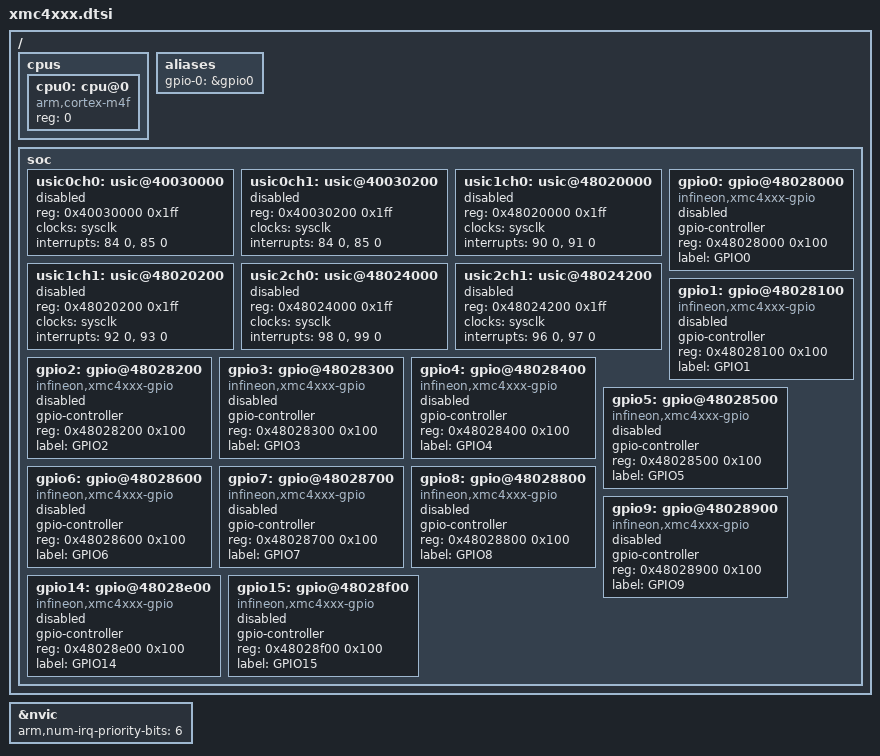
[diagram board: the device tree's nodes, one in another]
/*
 * Copyright (c) 2020 Linumiz
 * Author: Parthiban Nallathambi <parthiban@linumiz.com>
 *
 * SPDX-License-Identifier: Apache-2.0
 */

#include <arm/armv7-m.dtsi>
#include <dt-bindings/gpio/gpio.h>

/ {
	cpus {
		#address-cells = <1>;
		#size-cells = <0>;

		cpu0: cpu@0 {
			compatible = "arm,cortex-m4f";
			reg = <0>;
		};
	};

	aliases {
		gpio-0 = &gpio0; 	
	};

	soc {
		usic0ch0: usic@40030000 {
			#address-cells = <1>;
			#size-cells = <0>;
			reg = <0x40030000 0x1ff>;
			clocks = <&sysclk>;
			status = "disabled";
			interrupts = <84 0>, <85 0>;
			interrupt-names = "SR0", "SR1";
		};

		usic0ch1: usic@40030200 {
			#address-cells = <1>;
			#size-cells = <0>;
			reg = <0x40030200 0x1ff>;
			clocks = <&sysclk>;
			status = "disabled";
			interrupts = <84 0>, <85 0>;
			interrupt-names = "SR0", "SR1";
		};

		usic1ch0: usic@48020000 {
			#address-cells = <1>;
			#size-cells = <0>;
			reg = <0x48020000 0x1ff>;
			clocks = <&sysclk>;
			status = "disabled";
			interrupts = <90 0>, <91 0>;
			interrupt-names = "SR0", "SR1";
		};

		usic1ch1: usic@48020200 {
			#address-cells = <1>;
			#size-cells = <0>;
			reg = <0x48020200 0x1ff>;
			clocks = <&sysclk>;
			status = "disabled";
			interrupts = <92 0>, <93 0>;
			interrupt-names = "SR0", "SR1";
		};

		usic2ch0: usic@48024000 {
			#address-cells = <1>;
			#size-cells = <0>;
			reg = <0x48024000 0x1ff>;
			clocks = <&sysclk>;
			status = "disabled";
			interrupts = <98 0>, <99 0>;
			interrupt-names = "SR0", "SR1";
		};

		usic2ch1: usic@48024200 {
			#address-cells = <1>;
			#size-cells = <0>;
			reg = <0x48024200 0x1ff>;
			clocks = <&sysclk>;
			status = "disabled";
			interrupts = <96 0>, <97 0>;
			interrupt-names = "SR0", "SR1";
		};

		/* GPIO Interface */
		gpio0: gpio@48028000 {
			compatible = "infineon,xmc4xxx-gpio";
			gpio-controller;
			#gpio-cells = <2>;
			reg = <0x48028000 0x100>;
			label = "GPIO0";
			status = "disabled";
		};

		gpio1: gpio@48028100 {
			compatible = "infineon,xmc4xxx-gpio";
			gpio-controller;
			#gpio-cells = <2>;
			reg = <0x48028100 0x100>;
			label = "GPIO1";
			status = "disabled";
		};

		gpio2: gpio@48028200 {
			compatible = "infineon,xmc4xxx-gpio";
			gpio-controller;
			#gpio-cells = <2>;
			reg = <0x48028200 0x100>;
			label = "GPIO2";
			status = "disabled";
		};

		gpio3: gpio@48028300 {
			compatible = "infineon,xmc4xxx-gpio";
			gpio-controller;
			#gpio-cells = <2>;
			reg = <0x48028300 0x100>;
			label = "GPIO3";
			status = "disabled";
		};

		gpio4: gpio@48028400 {
			compatible = "infineon,xmc4xxx-gpio";
			gpio-controller;
			#gpio-cells = <2>;
			reg = <0x48028400 0x100>;
			label = "GPIO4";
			status = "disabled";
		};

		gpio5: gpio@48028500 {
			compatible = "infineon,xmc4xxx-gpio";
			gpio-controller;
			#gpio-cells = <2>;
			reg = <0x48028500 0x100>;
			label = "GPIO5";
			status = "disabled";
		};

		gpio6: gpio@48028600 {
			compatible = "infineon,xmc4xxx-gpio";
			gpio-controller;
			#gpio-cells = <2>;
			reg = <0x48028600 0x100>;
			label = "GPIO6";
			status = "disabled";
		};

		gpio7: gpio@48028700 {
			compatible = "infineon,xmc4xxx-gpio";
			gpio-controller;
			#gpio-cells = <2>;
			reg = <0x48028700 0x100>;
			label = "GPIO7";
			status = "disabled";
		};

		gpio8: gpio@48028800 {
			compatible = "infineon,xmc4xxx-gpio";
			gpio-controller;
			#gpio-cells = <2>;
			reg = <0x48028800 0x100>;
			label = "GPIO8";
			status = "disabled";
		};

		gpio9: gpio@48028900 {
			compatible = "infineon,xmc4xxx-gpio";
			gpio-controller;
			#gpio-cells = <2>;
			reg = <0x48028900 0x100>;
			label = "GPIO9";
			status = "disabled";
		};

		gpio14: gpio@48028e00 {
			compatible = "infineon,xmc4xxx-gpio";
			gpio-controller;
			#gpio-cells = <2>;
			reg = <0x48028e00 0x100>;
			label = "GPIO14";
			status = "disabled";
		};

		gpio15: gpio@48028f00 {
			compatible = "infineon,xmc4xxx-gpio";
			gpio-controller;
			#gpio-cells = <2>;
			reg = <0x48028f00 0x100>;
			label = "GPIO15";
			status = "disabled";
		};
	};
};

&nvic {
	arm,num-irq-priority-bits = <6>;
};
